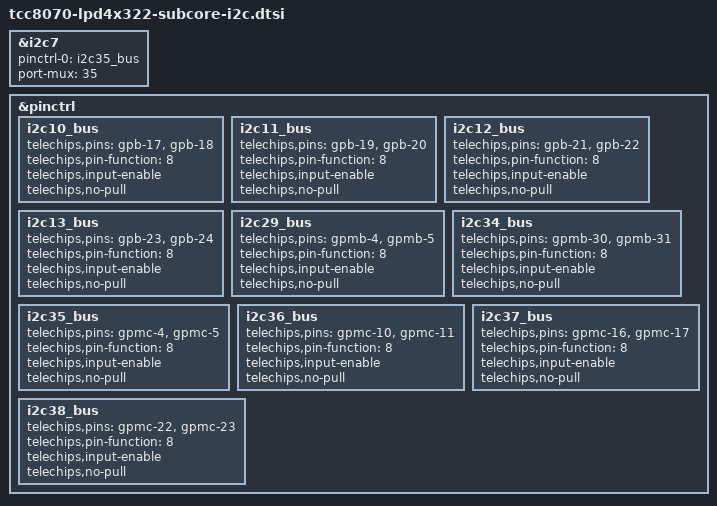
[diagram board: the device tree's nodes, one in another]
// SPDX-License-Identifier: (GPL-2.0-or-later OR MIT)
/*
 * Copyright (C) 2023 Telechips Inc.
 */

&i2c7 {
	pinctrl-names = "default";
	pinctrl-0 = <&i2c35_bus>;
	port-mux = <35>;
	status = "okay";
};

&pinctrl {
	/omit-if-no-ref/
	i2c10_bus: i2c10_bus {
		telechips,pins = "gpb-17", "gpb-18";
		telechips,pin-function = <8>;
		telechips,input-enable;
		telechips,no-pull;
	};

	/omit-if-no-ref/
	i2c11_bus: i2c11_bus {
		telechips,pins = "gpb-19", "gpb-20";
		telechips,pin-function = <8>;
		telechips,input-enable;
		telechips,no-pull;
	};

	/omit-if-no-ref/
	i2c12_bus: i2c12_bus {
		telechips,pins = "gpb-21", "gpb-22";
		telechips,pin-function = <8>;
		telechips,input-enable;
		telechips,no-pull;
	};

	/omit-if-no-ref/
	i2c13_bus: i2c13_bus {
		telechips,pins = "gpb-23", "gpb-24";
		telechips,pin-function = <8>;
		telechips,input-enable;
		telechips,no-pull;
	};

	/omit-if-no-ref/
	i2c29_bus: i2c29_bus {
		telechips,pins = "gpmb-4", "gpmb-5";
		telechips,pin-function = <8>;
		telechips,input-enable;
		telechips,no-pull;
	};

	/omit-if-no-ref/
	i2c34_bus: i2c34_bus {
		telechips,pins = "gpmb-30", "gpmb-31";
		telechips,pin-function = <8>;
		telechips,input-enable;
		telechips,no-pull;
	};

	/omit-if-no-ref/
	i2c35_bus: i2c35_bus {
		telechips,pins = "gpmc-4", "gpmc-5";
		telechips,pin-function = <8>;
		telechips,input-enable;
		telechips,no-pull;
	};

	/omit-if-no-ref/
	i2c36_bus: i2c36_bus {
		telechips,pins = "gpmc-10", "gpmc-11";
		telechips,pin-function = <8>;
		telechips,input-enable;
		telechips,no-pull;
	};

	/omit-if-no-ref/
	i2c37_bus: i2c37_bus {
		telechips,pins = "gpmc-16", "gpmc-17";
		telechips,pin-function = <8>;
		telechips,input-enable;
		telechips,no-pull;
	};

	/omit-if-no-ref/
	i2c38_bus: i2c38_bus {
		telechips,pins = "gpmc-22", "gpmc-23";
		telechips,pin-function = <8>;
		telechips,input-enable;
		telechips,no-pull;
	};
};
